# M471 register map
File version: 1.0
Registers are 32-bit, read-write, reset 0x0 unless marked. A register's access mark holds for its fields unless they carry their own. Offsets are from the block's base; [hi:lo] are bit positions; {n}, {i} and the like mark numbered series; 'fields as' and 'values as' point back to an identical list.

## CLK — CLK Register Map
Base 0x40000200
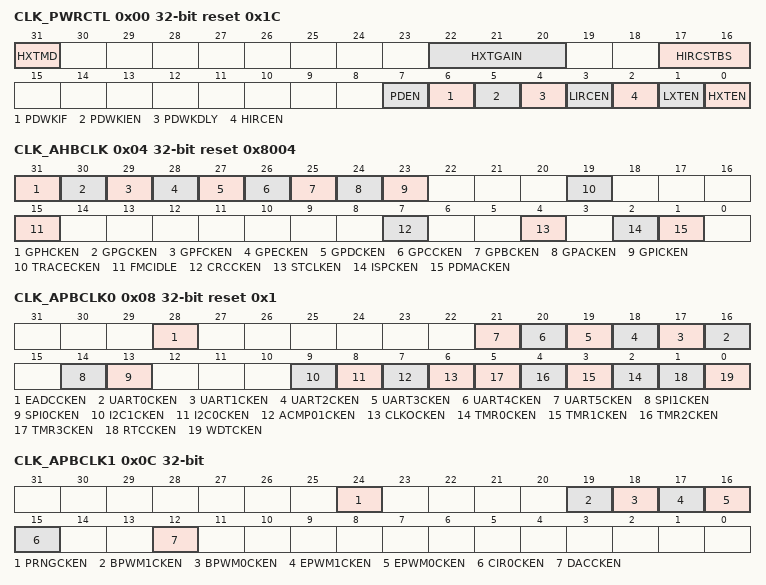
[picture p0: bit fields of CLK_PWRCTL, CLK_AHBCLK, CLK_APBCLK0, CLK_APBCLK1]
0x00 CLK_PWRCTL reset 0x1C — System Power-down Control Register
  [31] HXTMD — HXT Bypass Mode (Write Protect). This is a protected register. Please refer to open lock sequence to program it. Note 2: This bit is write protected. Refer to the SYS_REGCTL register.
    0=HXT work as crystal mode. PF.2 and PF.3 are configured as external high speed crystal (HXT) pins; 1=HXT works as external clock mode. PF.3 is configured as external clock input pin
  [22:20] HXTGAIN — HXT Gain Control Bit (Write Protect). This is a protected register. Please refer to open lock sequence to program it. Gain control is used to enlarge the gain of crystal to make sure crystal work normally. If gain control is enabled, crystal will consume more power than gain control off. Others: Reserved. Note: This bit is write protected. Refer to the SYS_REGLCTL register.
    0=HXT frequency is from 4 MHz to 8 MHz. HXT frequency is from 4 MHz to 8 MHz. (Crystal); 1=HXT frequency is from 8 MHz to 12 MHz. HXT frequency is from 8 MHz to 12 MHz. (Crystal); 2=HXT frequency is from 12 MHz to 16 MHz. HXT frequency is from 12 MHz to 16 MHz. (Crystal); 3=HXT frequency is from 16 MHz to 24 MHz. HXT frequency is from 16 MHz to 24 MHz. (Crystal); 4=HXT frequency is from 4 MHz to 8 MHz. (Resonator); 5=HXT frequency is from 8 MHz to 12 MHz. (Resonator); 6=HXT frequency is from 12 MHz to 16 MHz. (Resonator); 7=HXT frequency is from 16 MHz to 24 MHz. (Resonator)
  [17:16] HIRCSTBS — HIRC Stable Count Select (Write Protect). Others: Reserved. Note: This bit is write protected. Refer to the SYS_REGLCTL register.
    0=HIRC stable count = 512 clocks; 1=HIRC stable count = 1024 clocks; 2=HIRC stable count = 2048 clocks; 3=HIRC stable count = 256 clocks
  [7] PDEN — System Power-down Enable (Write Protect). When this bit is set to 1, Power-down mode is enabled and chip keeps active till the CPU sleep mode is also active and then the chip enters Power-down mode. When chip wakes up from Power-down mode, this bit is auto cleared. Users need to set this bit again for next Power-down. In Power-down mode, HXT and the HIRC will be disabled in this mode, but LXT and LIRC are not controlled by Power-down mode. In Power-down mode, the PLL and system clock are disabled, and ignored the clock source selection. The clocks of peripheral are not controlled by Power-down mode, if the peripheral clock source is from LXT or LIRC. Note: This bit is write protected. Refer to the SYS_REGLCTL register.
    0=Chip will not enter Power-down mode after CPU sleep command WFI; 1=Chip enters Power-down mode after CPU sleep command WFI
  [6] PDWKIF — Power-down Mode Wake-up Interrupt Status. Set by 'Power-down wake-up event', it indicates that resume from Power-down mode' The flag is set if any wake-up source is occurred. Refer Power Modes and Wake-up Sources chapter. Note 1: Write 1 to clear the bit to 0. Note 2: This bit works only if PDWKIEN (CLK_PWRCTL[5]) is set to 1.
  [5] PDWKIEN — Power-down Mode Wake-up Interrupt Enable Bit (Write Protect). Note 1: The interrupt will occur when both PDWKIF and PDWKIEN are high. Note 2: This bit is write protected. Refer to the SYS_REGLCTL register.
    0=Power-down mode wake-up interrupt Disabled; 1=Power-down mode wake-up interrupt Enabled
  [4] PDWKDLY — Enable the Wake-up Delay Counter (Write Protect). When the chip wakes up from Power-down mode, the clock control will delay certain clock cycles to wait system clock stable. The delayed clock cycle is 4096 clock cycles when chip works at 4~24 MHz external high speed crystal oscillator (HXT), and 256 clock cycles when chip works at 48 MHz internal high speed RC oscillator (HIRC). Note: This bit is write protected. Refer to the SYS_REGLCTL register.
    0=Clock cycles delay Disabled; 1=Clock cycles delay Enabled
  [3] LIRCEN — LIRC Enable Bit (Write Protect). Note: This bit is write protected. Refer to the SYS_REGLCTL register.
    0=38.4 kHz internal low speed RC oscillator (LIRC) Disabled; 1=38.4 kHz internal low speed RC oscillator (LIRC) Enabled
  [2] HIRCEN — HIRC Enable Bit (Write Protect). Note: This bit is write protected. Refer to the SYS_REGLCTL register.
    0=48 MHz internal high speed RC oscillator (HIRC) Disabled; 1=48 MHz internal high speed RC oscillator (HIRC) Enabled
  [1] LXTEN — LXT Enable Bit (Write Protect). Note 1: This bit is write protected. Refer to the SYS_REGLCTL register. Note 2: When LXT is enabled, GPF.4 and GPF.5 must be set as input mode.
    0=32.768 kHz external low speed crystal (LXT) Disabled; 1=32.768 kHz external low speed crystal (LXT) Enabled
  [0] HXTEN — HXT Enable Bit (Write Protect). Note 1: This bit is write protected. Refer to the SYS_REGLCTL register. Note 2: When HXT is enabled, GPF.2 and GPF.3 must be set as input mode.
    0=4~24 MHz external high speed crystal (HXT) Disabled; 1=4~24 MHz external high speed crystal (HXT) Enabled
0x04 CLK_AHBCLK reset 0x8004 — AHB Devices Clock Enable Control Register
  [31] GPHCKEN — GPIOH Clock Enable Bit
    0=GPIOH port clock Disabled; 1=GPIOH port clock Enabled
  [30] GPGCKEN — GPIOG Clock Enable Bit
    0=GPIOG port clock Disabled; 1=GPIOG port clock Enabled
  [29] GPFCKEN — GPIOF Clock Enable Bit
    0=GPIOF port clock Disabled; 1=GPIOF port clock Enabled
  [28] GPECKEN — GPIOE Clock Enable Bit
    0=GPIOE port clock Disabled; 1=GPIOE port clock Enabled
  [27] GPDCKEN — GPIOD Clock Enable Bit
    0=GPIOD port clock Disabled; 1=GPIOD port clock Enabled
  [26] GPCCKEN — GPIOC Clock Enable Bit
    0=GPIOC port clock Disabled; 1=GPIOC port clock Enabled
  [25] GPBCKEN — GPIOB Clock Enable Bit
    0=GPIOB port clock Disabled; 1=GPIOB port clock Enabled
  [24] GPACKEN — GPIOA Clock Enable Bit
    0=GPIOA port clock Disabled; 1=GPIOA port clock Enabled
  [23] GPICKEN — GPIOI Clock Enable Bit
    0=GPIOI port clock Disabled; 1=GPIOI port clock Enabled
  [19] TRACECKEN — TRACE Clock Enable Bit
    0=TRACE clock Disabled; 1=TRACE clock Enabled
  [15] FMCIDLE — Flash Memory Controller Clock Enable Bit in IDLE Mode
    0=FMC clock Disabled when chip is under IDLE mode; 1=FMC clock Enabled when chip is under IDLE mode
  [7] CRCCKEN — CRC Generator Controller Clock Enable Bit
    0=CRC peripheral clock Disabled; 1=CRC peripheral clock Enabled
  [4] STCLKEN — Cortex-M4 SysTick Clock Enable Bit
    0=Cortex-M4 sys tick clock Disabled; 1=Cortex-M4 sys tick clock Enabled
  [2] ISPCKEN — Flash ISP Controller Clock Enable Bit
    0=Flash ISP peripheral clock Disabled; 1=Flash ISP peripheral clock Enabled
  [1] PDMACKEN — PDMA Controller Clock Enable Bit
    0=PDMA peripheral clock Disabled; 1=PDMA peripheral clock Enabled
0x08 CLK_APBCLK0 reset 0x1 — APB Devices Clock Enable Control Register 0
  [28] EADCCKEN — Enhanced Analog-digital-converter (EADC) Clock Enable Bit
    0=EADC clock Disabled; 1=EADC clock Enabled
  [n+16] UART{n}CKEN (n=0..5) — UART{n} Clock Enable Bit
    0=UART{n} clock Disabled; 1=UART{n} clock Enabled
  [14] SPI1CKEN — SPI1 Clock Enable Bit
    0=SPI1 clock Disabled; 1=SPI1 clock Enabled
  [13] SPI0CKEN — SPI0 Clock Enable Bit
    0=SPI0 clock Disabled; 1=SPI0 clock Enabled
  [9] I2C1CKEN — I2C1 Clock Enable Bit
    0=I2C1 clock Disabled; 1=I2C1 clock Enabled
  [8] I2C0CKEN — I2C0 Clock Enable Bit
    0=I2C0 clock Disabled; 1=I2C0 clock Enabled
  [7] ACMP01CKEN — Analog Comparator 0/1 Clock Enable Bit
    0=Analog comparator 0/1 clock Disabled; 1=Analog comparator 0/1 clock Enabled
  [6] CLKOCKEN — CLKO Clock Enable Bit
    0=CLKO clock Disabled; 1=CLKO clock Enabled
  [n+2] TMR{n}CKEN (n=0..3) — Timer{n} Clock Enable Bit
    0=Timer{n} clock Disabled; 1=Timer{n} clock Enabled
  [1] RTCCKEN — Real-time-clock APB Interface Clock Enable Bit. This bit is used to control the RTC APB clock only.
    0=RTC clock Disabled; 1=RTC clock Enabled
  [0] WDTCKEN — Watchdog Timer Clock Enable Bit (Write Protect). Note: This bit is write protected. Refer to the SYS_REGLCTL register.
    0=Watchdog timer clock Disabled; 1=Watchdog timer clock Enabled
0x0C CLK_APBCLK1 — APB Devices Clock Enable Control Register 1
  [24] PRNGCKEN — PRNG Clock Enable Bit
    0=PRNG clock Disabled; 1=PRNG clock Enabled
  [19] BPWM1CKEN — BPWM1 Clock Enable Bit
    0=BPWM1 clock Disabled; 1=BPWM1 clock Enabled
  [18] BPWM0CKEN — BPWM0 Clock Enable Bit
    0=BPWM0 clock Disabled; 1=BPWM0 clock Enabled
  [17] EPWM1CKEN — EPWM1 Clock Enable Bit
    0=EPWM1 clock Disabled; 1=EPWM1 clock Enabled
  [16] EPWM0CKEN — EPWM0 Clock Enable Bit
    0=EPWM0 clock Disabled; 1=EPWM0 clock Enabled
  [15] CIR0CKEN — CIR0 Clock Enable Bit
    0=CIR0 clock Disabled; 1=CIR0 clock Enabled
  [12] DACCKEN — DAC Clock Enable Bit
    0=DAC clock Disabled; 1=DAC clock Enabled
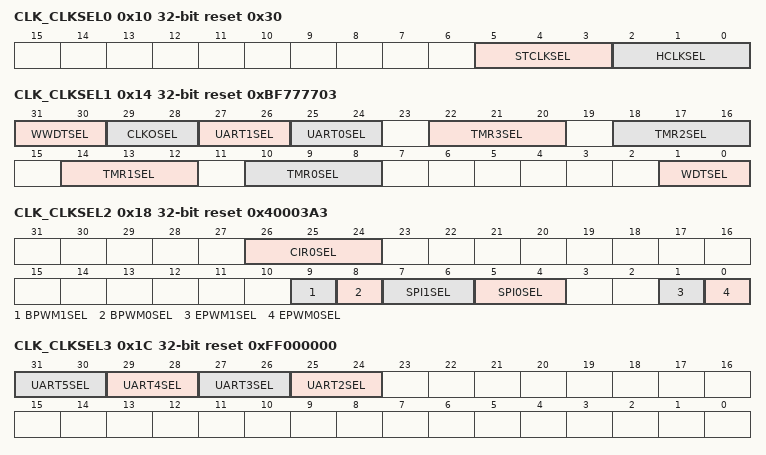
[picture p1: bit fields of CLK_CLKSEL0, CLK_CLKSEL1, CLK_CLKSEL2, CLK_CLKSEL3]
0x10 CLK_CLKSEL0 reset 0x30 (reset mask 0xFFFFFFF0) — Clock Source Select Control Register 0
  [5:3] STCLKSEL — Cortex-M4 SysTick Clock Source Selection (Write Protect). Note 2: This bit is write protected. Refer to the SYS_REGLCTL register.
    0=Clock source from HXT; 1=Clock source from LXT; 2=Clock source from HXT/2; 3=Clock source from HCLK/2; 7=Clock source from HIRC/2
  [2:0] HCLKSEL — HCLK Clock Source Selection (Write Protect). Before clock switching, the related clock sources (both pre-select and new-select) must be turned on. The default value is reloaded from the value of CFOSC (CONFIG0[26:24]) in user configuration register of Flash controller by any reset. Therefore the default value is either 000b or 111b. Note: This bit is write protected. Refer to the SYS_REGLCTL register.
    0=Clock source from HXT; 1=Clock source from LXT; 2=Clock source from PLL; 3=Clock source from LIRC; 7=Clock source from HIRC
0x14 CLK_CLKSEL1 reset 0xBF777703 — Clock Source Select Control Register 1
  [31:30] WWDTSEL — Window Watchdog Timer Clock Source Selection
    2=Clock source from HCLK/2048; 3=Clock source from internal low speed RC oscillator (LIRC)
  [29:28] CLKOSEL — Clock Divider Clock Source Selection
    0=Clock source from external high speed crystal oscillator (HXT); 1=Clock source from external low speed crystal oscillator (LXT); 2=Clock source from HCLK; 3=Clock source from internal high speed RC oscillator (HIRC)
  [27:26] UART1SEL — UART1 Clock Source Selection
    0=Clock source from external high speed crystal oscillator (HXT); 1=Clock source from PLL; 2=Clock source from external low speed crystal oscillator (LXT); 3=Clock source from internal high speed RC oscillator (HIRC)
  [25:24] UART0SEL — UART0 Clock Source Selection
    values as UART1SEL
  [22:20] TMR3SEL — TIMER3 Clock Source Selection
    0=Clock source from external high speed crystal oscillator (HXT); 1=Clock source from external low speed crystal oscillator (LXT); 2=Clock source from PCLK1; 3=Clock source from external clock TM3 pin; 5=Clock source from internal low speed RC oscillator (LIRC); 7=Clock source from internal high speed RC oscillator (HIRC)
  [18:16] TMR2SEL — TIMER2 Clock Source Selection
    0=Clock source from external high speed crystal oscillator (HXT); 1=Clock source from external low speed crystal oscillator (LXT); 2=Clock source from PCLK1; 3=Clock source from external clock TM2 pin; 5=Clock source from internal low speed RC oscillator (LIRC); 7=Clock source from internal high speed RC oscillator (HIRC)
  [14:12] TMR1SEL — TIMER1 Clock Source Selection
    0=Clock source from external high speed crystal oscillator (HXT); 1=Clock source from external low speed crystal oscillator (LXT); 2=Clock source from PCLK0; 3=Clock source from external clock TM1 pin; 5=Clock source from internal low speed RC oscillator (LIRC); 7=Clock source from internal high speed RC oscillator (HIRC)
  [10:8] TMR0SEL — TIMER0 Clock Source Selection
    0=Clock source from external high speed crystal oscillator (HXT); 1=Clock source from external low speed crystal oscillator (LXT); 2=Clock source from PCLK0; 3=Clock source from external clock TM0 pin; 5=Clock source from internal low speed RC oscillator (LIRC); 7=Clock source from internal high speed RC oscillator (HIRC)
  [1:0] WDTSEL — Watchdog Timer Clock Source Selection (Write Protect). Note: This bit is write protected. Refer to the SYS_REGLCTL register.
    1=Clock source from external low speed crystal oscillator (LXT); 2=Clock source from HCLK/2048; 3=Clock source from internal low speed RC oscillator (LIRC)
0x18 CLK_CLKSEL2 reset 0x40003A3 — Clock Source Select Control Register 2
  [26:24] CIR0SEL — CIR0 Clock Source Selection
    0=Clock source from external high speed crystal oscillator (HXT); 1=Clock source from external low speed crystal oscillator (LXT); 2=Clock source from Timer0 clock output (TM0); 3=Clock source from internal low speed RC oscillator (LIRC); 4=Clock source from internal high speed RC oscillator (HIRC)
  [9] BPWM1SEL — BPWM1 Clock Source Selection. The peripheral clock source of BPWM1 is defined by BPWM1SEL.
    0=Clock source from HCLK; 1=Clock source from PCLK1
  [8] BPWM0SEL — BPWM0 Clock Source Selection. The peripheral clock source of BPWM0 is defined by BPWM0SEL.
    0=Clock source from HCLK; 1=Clock source from PCLK0
  [7:6] SPI1SEL — SPI1 Clock Source Selection
    0=Clock source from external high speed crystal oscillator (HXT); 1=Clock source from PLL; 2=Clock source from PCLK0; 3=Clock source from internal high speed RC oscillator (HIRC)
  [5:4] SPI0SEL — SPI0 Clock Source Selection
    0=Clock source from external high speed crystal oscillator (HXT); 1=Clock source from PLL; 2=Clock source from PCLK1; 3=Clock source from internal high speed RC oscillator (HIRC)
  [1] EPWM1SEL — EPWM1 Clock Source Selection. The peripheral clock source of EPWM1 is defined by EPWM1SEL.
    0=Clock source from HCLK; 1=Clock source from PCLK1
  [0] EPWM0SEL — EPWM0 Clock Source Selection. The peripheral clock source of EPWM0 is defined by EPWM0SEL.
    0=Clock source from HCLK; 1=Clock source from PCLK0
0x1C CLK_CLKSEL3 reset 0xFF000000 — Clock Source Select Control Register 3
  [all] fields
    values as CLK_CLKSEL1.UART1SEL
  [2n+21:2n+20] UART{n}SEL (n=2..5) — UART{n} Clock Source Selection
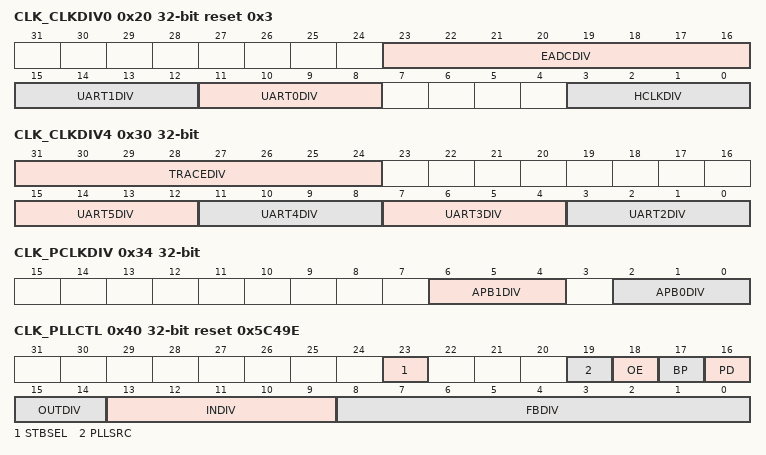
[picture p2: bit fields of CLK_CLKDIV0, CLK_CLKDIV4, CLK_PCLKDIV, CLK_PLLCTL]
0x20 CLK_CLKDIV0 reset 0x3 — Clock Divider Number Register 0
  [23:16] EADCDIV — EADC Clock Divide Number From EADC Clock Source
  [15:12] UART1DIV — UART1 Clock Divide Number From UART1 Clock Source
  [11:8] UART0DIV — UART0 Clock Divide Number From UART0 Clock Source
  [3:0] HCLKDIV — HCLK Clock Divide Number From HCLK Clock Source
0x30 CLK_CLKDIV4 — Clock Divider Number Register 4
  [31:24] TRACEDIV — Cortex M4 ETM Trace Clock Divide Number From ETM Trace Clock Source
  [4n-5:4n-8] UART{n}DIV (n=2..5) — UART{n} Clock Divide Number From UART{n} Clock Source
0x34 CLK_PCLKDIV — APB Clock Divider Register
  [6:4] APB1DIV — APB1 Clock Divider. APB1 clock can be divided from HCLK. Others: Reserved.
  [2:0] APB0DIV — APB0 Clock Divider. APB0 clock can be divided from HCLK. Others: Reserved.
0x40 CLK_PLLCTL reset 0x5C49E — PLL Control Register
  [23] STBSEL — PLL Stable Counter Selection (Write Protect). Note: This bit is write protected. Refer to the SYS_REGLCTL register.
    0=PLL stable time is 6144 PLL source clock (suitable for source clock is equal to or less than 12 MHz); 1=PLL stable time is 16128 PLL source clock (suitable for source clock is larger than 12 MHz)
  [19] PLLSRC — PLL Source Clock Selection (Write Protect). Note: This bit is write protected. Refer to the SYS_REGLCTL register.
    0=PLL source clock from 4~24 MHz external high-speed crystal oscillator (HXT); 1=PLL source clock from 48 MHz internal high-speed oscillator divided by 4 (HIRC/4)
  [18] OE — PLL OE (FOUT Enable) Pin Control (Write Protect). Note: This bit is write protected. Refer to the SYS_REGLCTL register.
    0=PLL FOUT Enabled; 1=PLL FOUT is fixed low
  [17] BP — PLL Bypass Control (Write Protect). Note: This bit is write protected. Refer to the SYS_REGLCTL register.
    0=PLL is in normal mode (default); 1=PLL clock output is same as PLL input clock FIN
  [16] PD — Power-down Mode (Write Protect). If set the PDEN bit to 1 in CLK_PWRCTL register, the PLL will enter Power-down mode, too. Note: This bit is write protected. Refer to the SYS_REGLCTL register.
    0=PLL is in normal mode; 1=PLL is in Power-down mode (default)
  [15:14] OUTDIV — PLL Output Divider Control (Write Protect). Refer to the formulas below the table. Note: This bit is write protected. Refer to the SYS_REGLCTL register.
  [13:9] INDIV — PLL Input Divider Control (Write Protect). Refer to the formulas below the table. Note: This bit is write protected. Refer to the SYS_REGLCTL register.
  [8:0] FBDIV — PLL Feedback Divider Control (Write Protect). Refer to the formulas below the table. Note: This bit is write protected. Refer to the SYS_REGLCTL register.
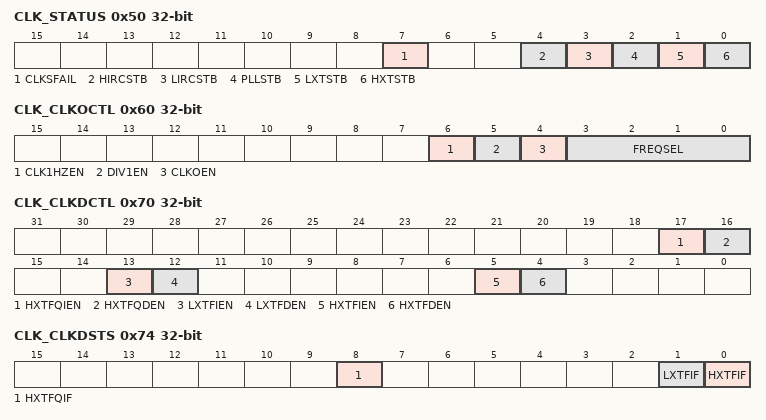
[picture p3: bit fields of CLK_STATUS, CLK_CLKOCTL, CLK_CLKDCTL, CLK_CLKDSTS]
0x50 CLK_STATUS ro (reset mask 0xFFFFFF00) — Clock Status Monitor Register
  [7] CLKSFAIL — Clock Switching Fail Flag (Read Only). This bit is updated when software switches system clock source. If switch target clock is stable, this bit will be set to 0. If switch target clock is not stable, this bit will be set to 1. Note: Write 1 to clear the bit to 0.
    0=Clock switching success; 1=Clock switching failure
  [4] HIRCSTB — HIRC Clock Source Stable Flag (Read Only)
    0=48 MHz internal high speed RC oscillator (HIRC) clock is not stable or disabled; 1=48 MHz internal high speed RC oscillator (HIRC) clock is stable and enabled
  [3] LIRCSTB — LIRC Clock Source Stable Flag (Read Only)
    0=38.4 kHz internal low speed RC oscillator (LIRC) clock is not stable or disabled; 1=38.4 kHz internal low speed RC oscillator (LIRC) clock is stable and enabled
  [2] PLLSTB — Internal PLL Clock Source Stable Flag (Read Only)
    0=Internal PLL clock is not stable or disabled; 1=Internal PLL clock is stable and enabled
  [1] LXTSTB — LXT Clock Source Stable Flag (Read Only)
    0=32.768 kHz external low speed crystal oscillator (LXT) clock is not stable or disabled; 1=32.768 kHz external low speed crystal oscillator (LXT) clock is stabled and enabled
  [0] HXTSTB — HXT Clock Source Stable Flag (Read Only)
    0=4~24 MHz external high speed crystal oscillator (HXT) clock is not stable or disabled; 1=4~24 MHz external high speed crystal oscillator (HXT) clock is stable and enabled
0x60 CLK_CLKOCTL — Clock Output Control Register
  [6] CLK1HZEN — Clock Output 1Hz Enable Bit. Note: Output for 32.768 kHz(LXT) or 38 kHz(LIRC) based on RTCCKSEL(RTC_LXTCTL[7]).
    0=1 Hz clock output for 32.768 kHz or 38 kHz frequency compensation Disabled; 1=1 Hz clock output for 32.768 kHz or 38 kHz frequency compensation Enabled
  [5] DIV1EN — Clock Output Divide One Enable Bit
    0=Clock Output will output clock with source frequency divided by FREQSEL; 1=Clock Output will output clock with source frequency
  [4] CLKOEN — Clock Output Enable Bit
    0=Clock Output function Disabled; 1=Clock Output function Enabled
  [3:0] FREQSEL — Clock Output Frequency Selection. The formula of output frequency is: Fin is the input clock frequency. Fout is the frequency of divider output clock. N is the 4-bit value of FREQSEL[3:0].
0x70 CLK_CLKDCTL — Clock Fail Detector Control Register
  [17] HXTFQIEN — HXT Clock Frequency Range Detector Interrupt Enable Bit
    0=4~24 MHz external high speed crystal oscillator (HXT) clock frequency range detector fail interrupt Disabled; 1=4~24 MHz external high speed crystal oscillator (HXT) clock frequency range detector fail interrupt Enabled
  [16] HXTFQDEN — HXT Clock Frequency Range Detector Enable Bit
    0=4~24 MHz external high speed crystal oscillator (HXT) clock frequency range detector Disabled; 1=4~24 MHz external high speed crystal oscillator (HXT) clock frequency range detector Enabled
  [13] LXTFIEN — LXT Clock Fail Interrupt Enable Bit
    0=32.768 kHz external low speed crystal oscillator (LXT) clock fail interrupt Disabled; 1=32.768 kHz external low speed crystal oscillator (LXT) clock fail interrupt Enabled
  [12] LXTFDEN — LXT Clock Fail Detector Enable Bit
    0=32.768 kHz external low speed crystal oscillator (LXT) clock fail detector Disabled; 1=32.768 kHz external low speed crystal oscillator (LXT) clock fail detector Enabled
  [5] HXTFIEN — HXT Clock Fail Interrupt Enable Bit
    0=4~24 MHz external high speed crystal oscillator (HXT) clock fail interrupt Disabled; 1=4~24 MHz external high speed crystal oscillator (HXT) clock fail interrupt Enabled
  [4] HXTFDEN — HXT Clock Fail Detector Enable Bit
    0=4~24 MHz external high speed crystal oscillator (HXT) clock fail detector Disabled; 1=4~24 MHz external high speed crystal oscillator (HXT) clock fail detector Enabled
0x74 CLK_CLKDSTS — Clock Fail Detector Status Register
  [8] HXTFQIF — HXT Clock Frequency Range Detector Interrupt Flag. Note: Write 1 to clear the bit to 0.
    0=4~24 MHz external high speed crystal oscillator (HXT) clock frequency is normal; 1=4~24 MHz external high speed crystal oscillator (HXT) clock frequency is abnormal
  [1] LXTFIF — LXT Clock Fail Interrupt Flag. Note: Write 1 to clear the bit to 0.
    0=32.768 kHz external low speed crystal oscillator (LXT) clock is normal; 1=32.768 kHz external low speed crystal oscillator (LXT) stops
  [0] HXTFIF — HXT Clock Fail Interrupt Flag. Note: Write 1 to clear the bit to 0.
    0=4~24 MHz external high speed crystal oscillator (HXT) clock is normal; 1=4~24 MHz external high speed crystal oscillator (HXT) clock stops
0x78 CLK_CDUPB — Clock Frequency Range Detector Upper Boundary Register
  [10:0] UPERBD — HXT Clock Frequency Range Detector Upper Boundary Value. The bits define the maximum value of frequency range detector window. When HXT frequency higher than this maximum frequency value, the HXT Clock Frequency Range Detector Interrupt Flag will be set to 1.
0x7C CLK_CDLOWB — Clock Frequency Range Detector Lower Boundary Register
  [10:0] LOWERBD — HXT Clock Frequency Range Detector Lower Boundary Value. The bits define the minimum value of frequency range detector window. When HXT frequency lower than this minimum frequency value, the HXT Clock Frequency Range Detector Interrupt Flag will be set to 1.
0x90 CLK_PMUCTL — Power Manager Control Register
  [2:0] PDMSEL — Power-down Mode Selection (Write Protect). This is a protected bit. Please refer to open lock sequence to program it. These bits control chip Power-down mode grade selection when CPU executes WFI/WFE instruction. Note: This bit is write protected. Refer to the SYS_REGLCTL register.
    0=Power-down mode is selected. (NPD)
